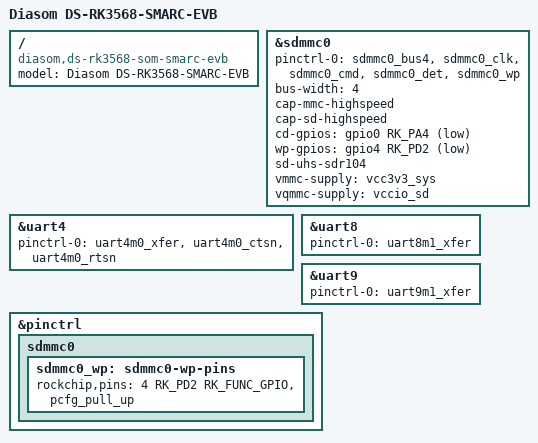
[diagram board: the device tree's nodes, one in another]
/* SPDX-License-Identifier: GPL-2.0+ */
/* SPDX-FileCopyrightText: Alexander Shiyan <shc_work@mail.ru> */

/dts-v1/;

#include "rk3568-diasom-som-smarc.dtsi"

/ {
	model = "Diasom DS-RK3568-SMARC-EVB";
	compatible = "diasom,ds-rk3568-som-smarc-evb",
		     "diasom,ds-rk3568-som-smarc",
		     "diasom,ds-rk3568-som",
		     "rockchip,rk3568";
};

&sdmmc0 {
	pinctrl-names = "default";
	pinctrl-0 = <
		&sdmmc0_bus4 &sdmmc0_clk &sdmmc0_cmd &sdmmc0_det &sdmmc0_wp
	>;
	bus-width = <4>;
	cap-mmc-highspeed;
	cap-sd-highspeed;
	cd-gpios = <&gpio0 RK_PA4 GPIO_ACTIVE_LOW>;
	wp-gpios = <&gpio4 RK_PD2 GPIO_ACTIVE_LOW>;
	sd-uhs-sdr104;
	vmmc-supply = <&vcc3v3_sys>;
	vqmmc-supply = <&vccio_sd>;
	status = "okay";
};

&uart4 {
	pinctrl-0 = <&uart4m0_xfer &uart4m0_ctsn &uart4m0_rtsn>;
	status = "okay";
};

&uart8 {
	pinctrl-0 = <&uart8m1_xfer>;
	status = "okay";
};

&uart9 {
	pinctrl-0 = <&uart9m1_xfer>;
	status = "okay";
};

&pinctrl {
	sdmmc0 {
		sdmmc0_wp: sdmmc0-wp-pins {
			rockchip,pins =
				<4 RK_PD2 RK_FUNC_GPIO &pcfg_pull_up>;		/* SDMMC0_WP */
		};
	};
};
